AUTOSAR XML (schema 4-0-3)
package /ComponentTypes
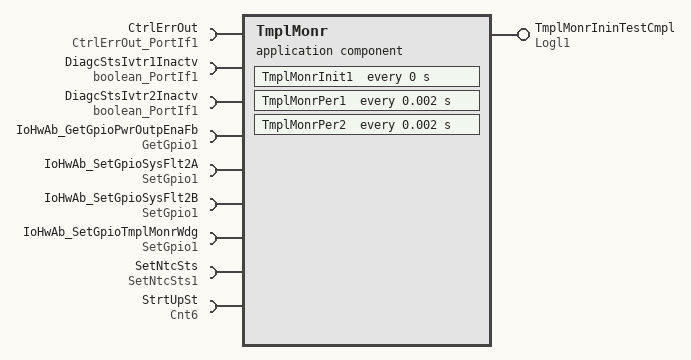
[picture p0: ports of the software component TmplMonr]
  application sw component type TmplMonr
    provide port TmplMonrIninTestCmpl: nonqueued-sender-com-spec{data-element=Logl, init-value=0}, provided-interface=Logl1
    9 x require port:
      CtrlErrOut: required-interface=CtrlErrOut_PortIf1
      DiagcStsIvtr1Inactv: nonqueued-receiver-com-spec{data-element=Logl, filter=data-filter-type=ALWAYS, init-value=0}, required-interface=boolean_PortIf1
      DiagcStsIvtr2Inactv: nonqueued-receiver-com-spec{data-element=Logl, filter=data-filter-type=ALWAYS, init-value=0}, required-interface=boolean_PortIf1
      IoHwAb_GetGpioPwrOutpEnaFb: required-interface=GetGpio1
      IoHwAb_SetGpioSysFlt2A: required-interface=SetGpio1
      IoHwAb_SetGpioSysFlt2B: required-interface=SetGpio1
      IoHwAb_SetGpioTmplMonrWdg: required-interface=SetGpio1
      SetNtcSts: required-interface=SetNtcSts1
      StrtUpSt: nonqueued-receiver-com-spec{data-element=Val, filter=data-filter-type=ALWAYS, init-value=0}, required-interface=Cnt6
    behavior TmplMonr_InternalBehavior: data-type-mapping=Nexteer
      ar-typed-per-instance-memorys:
        6 x data, all with sw-calibration-access=READ-ONLY:
          TmplMonrIninCntr: type=uint8
          TmplMonrIninTestCmplFlg: type=Logl1
          TmplMonrNtc40PrmByte: type=uint8
          TmplMonrSpiReadWrOrderFlg1: type=Logl1
          TmplMonrSpiReadWrOrderFlg2: type=Logl1
          TmplMonrWdgRstrtCnt: type=uint8
      timing event TmplMonr_InitEvent: start-on-event=TmplMonrInit1, period=0
      timing event TMT_TmplMonrPer1: start-on-event=TmplMonrPer1, period=0.002
      timing event TMT_TmplMonrPer2: start-on-event=TmplMonrPer2, period=0.002
      runnable TmplMonrInit1
        data-send-points:
          access SEND_TmplMonIninTestCmpl_Logl: accessed-variable=TmplMonrIninTestCmpl.Logl
        sync call SC_IoHwAb_SetGpioSysFlt2A_Oper: operation=IoHwAb_SetGpioSysFlt2A.Oper, timeout=0
        sync call SC_IoHwAb_SetGpioSysFlt2B_Oper: operation=IoHwAb_SetGpioSysFlt2B.Oper, timeout=0
      runnable TmplMonrPer1
        data-receive-point-by-arguments:
          access REC_StrtUpSt_Val: accessed-variable=StrtUpSt.Val
        data-send-points:
          access SEND_TmplMonIninTestCmpl_Logl: accessed-variable=TmplMonrIninTestCmpl.Logl
        4 x sync call, all with timeout=0:
          SC_CtrlErrOut_Oper: operation=CtrlErrOut.Oper
          SC_IoHwAb_GetGpioPwrOutEnaFb_Oper: operation=IoHwAb_GetGpioPwrOutpEnaFb.Oper
          SC_IoHwAb_SetGpioTmplMonrWdg_Oper: operation=IoHwAb_SetGpioTmplMonrWdg.Oper
          SC_SetNtcSts_Oper: operation=SetNtcSts.Oper
      runnable TmplMonrPer2
        data-receive-point-by-arguments:
          access REC_DiagcStsIvtr1Inactv_Logl: accessed-variable=DiagcStsIvtr1Inactv.Logl
          access REC_DiagcStsIvtr2Inactv_Logl: accessed-variable=DiagcStsIvtr2Inactv.Logl
          access REC_StrtUpSt_Val: accessed-variable=StrtUpSt.Val
        sync call SC_IoHwAb_SetGpioSysFlt2A_Oper: operation=IoHwAb_SetGpioSysFlt2A.Oper, timeout=0
        sync call SC_IoHwAb_SetGpioSysFlt2B_Oper: operation=IoHwAb_SetGpioSysFlt2B.Oper, timeout=0
        sync call SC_IoHwAb_SetGpioTmplMonrWdg_Oper: operation=IoHwAb_SetGpioTmplMonrWdg.Oper, timeout=0
  swc implementation TmplMonr_Implementation: behavior=TmplMonr_InternalBehavior
    code-descriptors:
      code Default: artifact-descriptors=autosar-engineering-object={short-label=Default, category=SWSRC}
